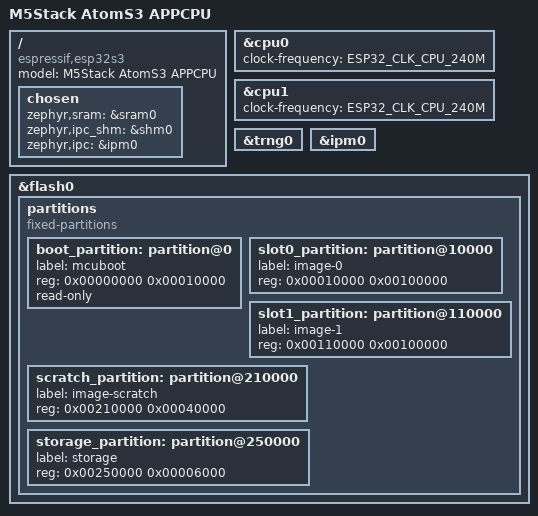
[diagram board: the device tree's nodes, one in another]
/*
 * Copyright (c) 2023 Espressif Systems (Shanghai) Co., Ltd.
 *
 * SPDX-License-Identifier: Apache-2.0
 */
/dts-v1/;

#include <espressif/esp32s3/esp32s3_appcpu.dtsi>
/ {
	model = "M5Stack AtomS3 APPCPU";
	compatible = "espressif,esp32s3";

	chosen {
		zephyr,sram = &sram0;
		zephyr,ipc_shm = &shm0;
		zephyr,ipc = &ipm0;
	};
};

&cpu0 {
	clock-frequency = <ESP32_CLK_CPU_240M>;
};

&cpu1 {
	clock-frequency = <ESP32_CLK_CPU_240M>;
};

&trng0 {
	status = "okay";
};

&ipm0 {
	status = "okay";
};

&flash0 {
	status = "okay";
	partitions {
		compatible = "fixed-partitions";
		#address-cells = <1>;
		#size-cells = <1>;

		/* Reserve 64kB for the bootloader */
		boot_partition: partition@0 {
			label = "mcuboot";
			reg = <0x00000000 0x00010000>;
			read-only;
		};

		/* Reserve 1024kB for the application in slot 0 */
		slot0_partition: partition@10000 {
			label = "image-0";
			reg = <0x00010000 0x00100000>;
		};

		/* Reserve 1024kB for the application in slot 1 */
		slot1_partition: partition@110000 {
			label = "image-1";
			reg = <0x00110000 0x00100000>;
		};

		/* Reserve 256kB for the scratch partition */
		scratch_partition: partition@210000 {
			   label = "image-scratch";
			   reg = <0x00210000 0x00040000>;
		};

		storage_partition: partition@250000 {
			label = "storage";
			reg = <0x00250000 0x00006000>;
		};
	};
};
